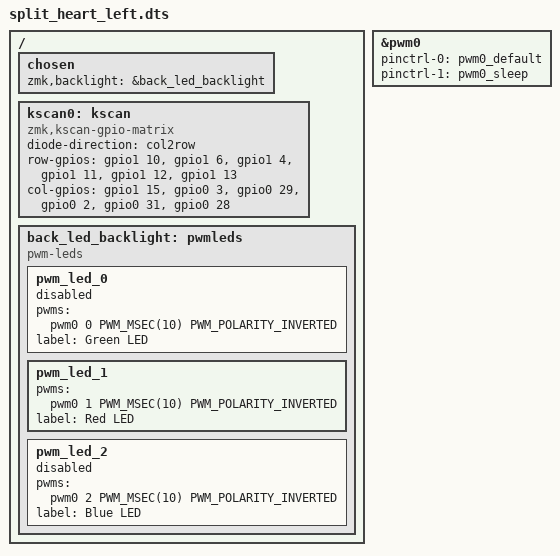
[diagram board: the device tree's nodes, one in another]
// This file was generated from a template. Edit it to match your keyboard.
// See https://zmk.dev/docs/development/hardware-integration/new-shield for more
// instructions.

#include "split_heart.dtsi"
#include "split_heart_left-pinctrl.dtsi"

#include <dt-bindings/zmk/backlight.h>

/{
    chosen {
        zmk,backlight = &back_led_backlight;
    };

    kscan0: kscan {
        compatible = "zmk,kscan-gpio-matrix";

        diode-direction = "col2row";
        
        row-gpios
            = <&gpio1 10 (GPIO_ACTIVE_HIGH | GPIO_PULL_DOWN)> // RW 1 (top row)
            , <&gpio1  6 (GPIO_ACTIVE_HIGH | GPIO_PULL_DOWN)> // RW 2
            , <&gpio1  4 (GPIO_ACTIVE_HIGH | GPIO_PULL_DOWN)> // RW 3
            , <&gpio1 11 (GPIO_ACTIVE_HIGH | GPIO_PULL_DOWN)> // RW 4 
            , <&gpio1 12 (GPIO_ACTIVE_HIGH | GPIO_PULL_DOWN)> // RW 5 (bottom row)
            , <&gpio1 13 (GPIO_ACTIVE_HIGH | GPIO_PULL_DOWN)> // RW 6 (thumb cluster)
            ;

        col-gpios
            = <&gpio1 15 GPIO_ACTIVE_HIGH> // Col 1  (Outer)
            , <&gpio0  3 GPIO_ACTIVE_HIGH> // Col 2 
            , <&gpio0 29 GPIO_ACTIVE_HIGH> // Col 3
            , <&gpio0  2 GPIO_ACTIVE_HIGH> // Col 4 
            , <&gpio0 31 GPIO_ACTIVE_HIGH> // Col 5
            , <&gpio0 28 GPIO_ACTIVE_HIGH> // Col 6  (Inner)
            ;
    };

    back_led_backlight: pwmleds {
        compatible = "pwm-leds";
        pwm_led_0 {
            pwms = <&pwm0 0 PWM_MSEC(10) PWM_POLARITY_INVERTED>;
            label = "Green LED";
            status = "disabled";
        };
        pwm_led_1 {
            pwms = <&pwm0 1 PWM_MSEC(10) PWM_POLARITY_INVERTED>;
            label = "Red LED";
            status = "okay";
        };
        pwm_led_2 {
            pwms = <&pwm0 2 PWM_MSEC(10) PWM_POLARITY_INVERTED>;
            label = "Blue LED";
            status = "disabled";
        };
    };
};

&pwm0 {
    status = "okay";
    pinctrl-0 = <&pwm0_default>;
    pinctrl-1 = <&pwm0_sleep>;
    pinctrl-names = "default", "sleep";
};
